# G32F031 register map
File version: 1.0
CPU: CM0PLUS r0p1, little endian, no MPU, no FPU, 2 interrupt priority bits
Registers are 32-bit, read-write, reset 0x0 unless marked. A register's access mark holds for its fields unless they carry their own. Offsets are from the block's base; [hi:lo] are bit positions; {n}, {i} and the like mark numbered series; 'fields as' and 'values as' point back to an identical list.

## DMA — DMA controller
Base 0x40020000
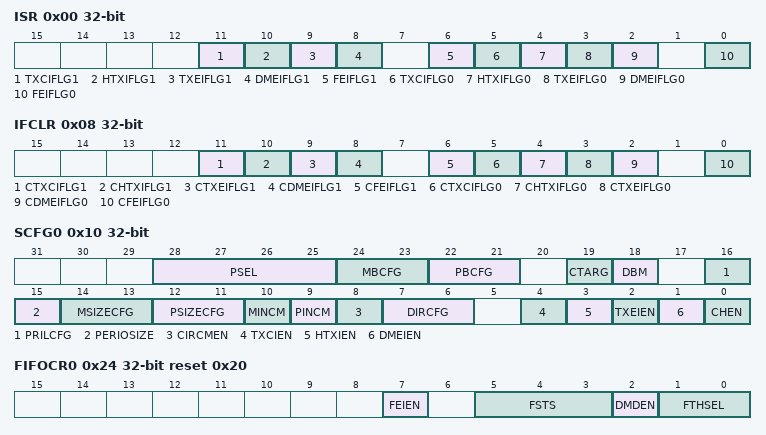
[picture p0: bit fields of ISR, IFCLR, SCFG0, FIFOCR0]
0x00 ISR ro — Interrupt Status Register
  [11] TXCIFLG1 — Stream 1 transfer complete interrupt flag
  [10] HTXIFLG1 — Stream 1 half transfer interrupt flag
  [9] TXEIFLG1 — Stream 1 transfer error interrupt flag
  [8] DMEIFLG1 — Stream 1 direct mode error interrupt flag
  [6] FEIFLG1 — Stream 1 FIFO error interrupt flag
  [5] TXCIFLG0 — Stream 0 transfer complete interrupt flag
  [4] HTXIFLG0 — Stream 0 half transfer interrupt flag
  [3] TXEIFLG0 — Stream 0 transfer error interrupt flag
  [2] DMEIFLG0 — Stream 0 direct mode error interrupt flag
  [0] FEIFLG0 — Stream 0 FIFO error interrupt flag
0x08 IFCLR — Interrupt Flag Clear Register
  [11] CTXCIFLG1 — Stream 1 clear transfer complete interrupt flag
  [10] CHTXIFLG1 — Stream 1 clear half transfer interrupt flag
  [9] CTXEIFLG1 — Stream 1 clear transfer error interrupt flag
  [8] CDMEIFLG1 — Stream 1 clear direct mode error interrupt flag
  [6] CFEIFLG1 — Stream 1 clear FIFO error interrupt flag
  [5] CTXCIFLG0 — Stream 0 clear transfer complete interrupt flag
  [4] CHTXIFLG0 — Stream 0 clear half transfer interrupt flag
  [3] CTXEIFLG0 — Stream 0 clear transfer error interrupt flag
  [2] CDMEIFLG0 — Stream 0 clear direct mode error interrupt flag
  [0] CFEIFLG0 — Stream 0 clear FIFO error interrupt flag
0x10 SCFG0
  [28:25] PSEL — Channel selection
  [24:23] MBCFG — Memory burst transfer configuration
  [22:21] PBCFG — Peripheral burst transfer configuration
  [19] CTARG — Current target (only in double buffer mode)
  [18] DBM — Double buffer mode
  [16] PRILCFG — Priority level
  [15] PERIOSIZE — Peripheral increment offset size
  [14:13] MSIZECFG — Memory data size
  [12:11] PSIZECFG — Peripheral data size
  [10] MINCM — Memory increment mode
  [9] PINCM — Peripheral increment mode
  [8] CIRCMEN — Circular mode
  [7:6] DIRCFG — Data transfer direction
  [4] TXCIEN — Transfer complete interrupt enable
  [3] HTXIEN — Half transfer interrupt enable
  [2] TXEIEN — Transfer error interrupt enable
  [1] DMEIEN — Direct mode error interrupt enable
  [0] CHEN — Stream enable / flag stream ready when read low
0x14 NDATA0
  [15:0] NDATA — Number of data items to transfer
0x18 PADDR0
  [31:0] PADDR — Peripheral address
0x1C M0ADDR0
  [31:0] M0ADDR — Memory 0 address
0x20 M1ADDR0
  [31:0] M1ADDR — Memory 1 address (used in case of Double buffer mode)
0x24 FIFOCR0 access per field reset 0x20
  [7] FEIEN rw — FIFO error interrupt enable
  [5:3] FSTS ro — FIFO status
  [2] DMDEN rw — Direct mode disable
  [1:0] FTHSEL rw — FIFO threshold selection
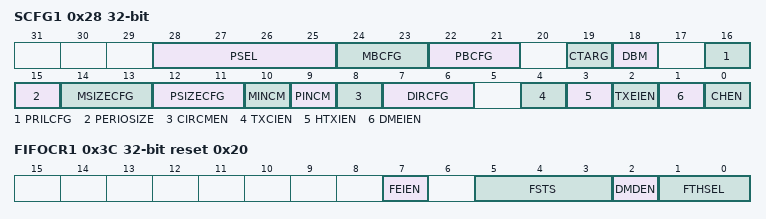
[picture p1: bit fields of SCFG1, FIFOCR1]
0x28 SCFG1
  fields as SCFG0
0x2C NDATA1
  [15:0] NDATA — Number of data items to transfer
0x30 PADDR1
  [31:0] PADDR — Peripheral address
0x34 M0ADDR1 reset 0xFFF0000
  [31:0] M0ADDR — Memory 0 address
0x38 M1ADDR1
  fields as M1ADDR0
0x3C FIFOCR1 access per field reset 0x20
  fields as FIFOCR0

## EINT — External interrupt/event controller
Base 0x40000800
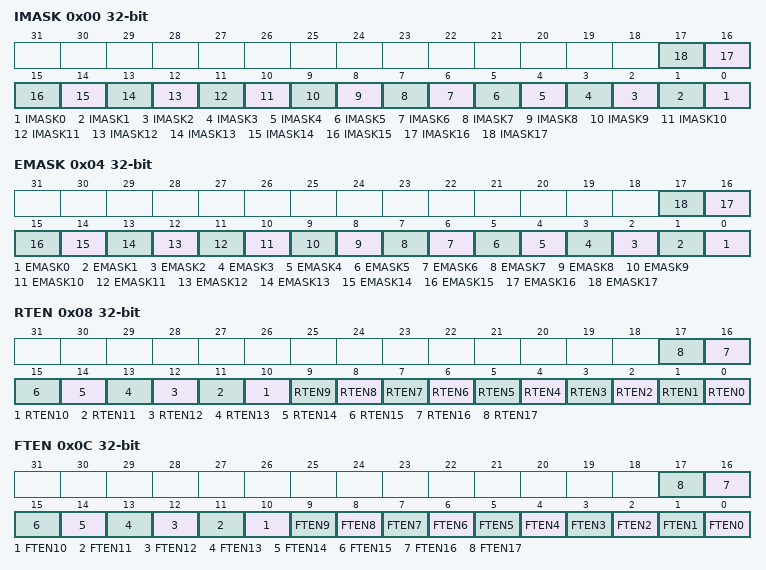
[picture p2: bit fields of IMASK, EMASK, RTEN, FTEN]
0x00 IMASK
  [n] IMASK{n} (n=0..17) — /
0x04 EMASK
  [n] EMASK{n} (n=0..17) — /
0x08 RTEN
  [n] RTEN{n} (n=0..17) — /
0x0C FTEN
  [n] FTEN{n} (n=0..17) — /
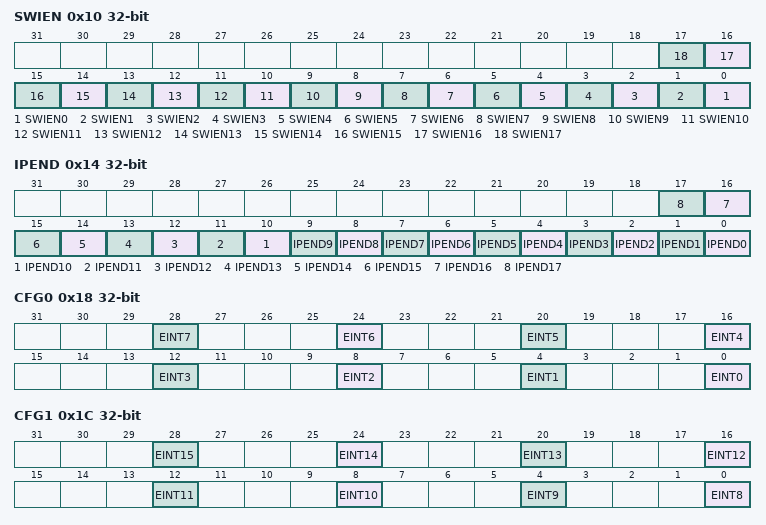
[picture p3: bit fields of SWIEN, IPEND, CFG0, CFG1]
0x10 SWIEN
  [n] SWIEN{n} (n=0..17) — /
0x14 IPEND
  [n] IPEND{n} (n=0..17) — /
0x18 CFG0
  [4n] EINT{n} (n=0..7) — /
0x1C CFG1
  [4n-32] EINT{n} (n=8..15) — /

## FLASH — Flash memory controller
Base 0x40020800
0x00 WKEY — /
  [0] WKEY — Status 1: Unlocked. Status 0: Locked
0x04 MKEY — /
  [0] MKEY — Status 1: Unlocked. Status 0: Locked
0x0C NVRCKEY — /
  [0] NVRCKEY — Status 1: Unlocked. Status 0: Locked
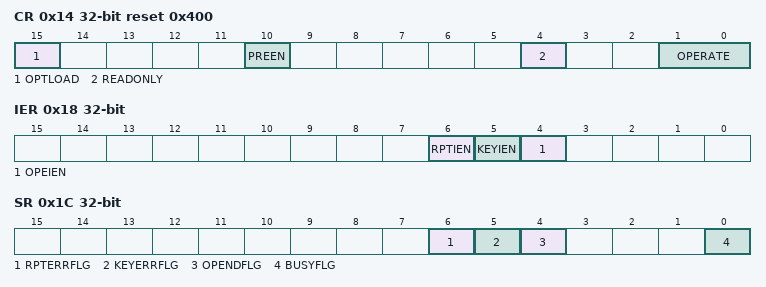
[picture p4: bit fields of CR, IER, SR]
0x14 CR reset 0x400 — /
  [15] OPTLOAD — The option byte is forcibly updated. When the data written to the high 16 bits is 0xa5a5 at the same time, the bit can be written as 1. When it is written as 1, the bit forcibly reloads the option byte, which will trigger a system reset. 0: Invalid 1: Valid
  [10] PREEN — Pre fetch enable.
  [4] READONLY — Flash ip read-only control, cannot be erased/written.
  [1:0] OPERATE — Flash operation type configuration
0x18 IER — /
  [6] RPTIEN — Flash Read/Write Protection Interrupt Enable
  [5] KEYIEN — Flash KEY Error Interrupt Enable
  [4] OPEIEN — Flash Erase End Interrupt Enable
0x1C SR access per field — /
  [6] RPTERRFLG rw — FLASH read and write protection error interrupt
  [5] KEYERRFLG rw — Flash KEY error interrupt, not unlocking flash erase.
  [4] OPENDFLG rw — FLASH erase finish interrupt
  [0] BUSYFLG ro — FLASH erase BUSY bit
0x20 CR1 reset 0x3 — /
  [1:0] LATENCY — The default value for the delay period on power-up at 64mhz (48mhz) is 2.
